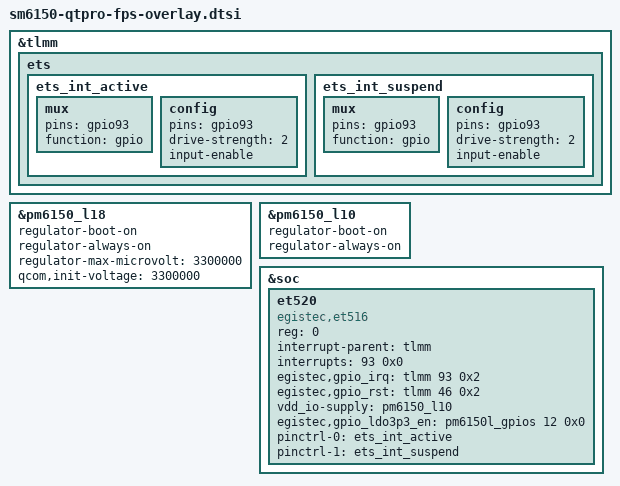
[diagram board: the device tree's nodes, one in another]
&tlmm {
	ets {
		ets_int_active: ets_int_active {
			/* INTERRUPT */
			mux {
				pins = "gpio93";
				function = "gpio";
			};

			config {
				pins = "gpio93";
				drive-strength = <2>; /* 2 MA */
				input-enable;
			};
		};
		ets_int_suspend: ets_int_suspend {
			/* INTERRUPT */
			mux {
				pins = "gpio93";
				function = "gpio";
			};

			config {
				pins = "gpio93";
				drive-strength = <2>; /* 2 MA */
				input-enable;
			};
		};
	};
};

&pm6150_l18 {
	regulator-boot-on;
	regulator-always-on;
	regulator-max-microvolt = <3300000>;
	qcom,init-voltage = <3300000>;
	status = "ok";
};

&pm6150_l10 {
	regulator-boot-on;
	regulator-always-on;
	status = "ok";
};

&soc {
	et520: et520 {
		compatible = "egistec,et516";
		status = "ok";
		reg = <0>;
		interrupt-parent = <&tlmm>;
		interrupts = <93 0x0>;
		egistec,gpio_irq = <&tlmm 93 0x2>;
		egistec,gpio_rst = <&tlmm 46 0x2>;
		vdd_io-supply = <&pm6150_l10>;
		egistec,gpio_ldo3p3_en = <&pm6150l_gpios 12 0x0>;
		pinctrl-names = "default", "suspend";
		pinctrl-0 = <&ets_int_active>;
		pinctrl-1 = <&ets_int_suspend>;
	};
};
